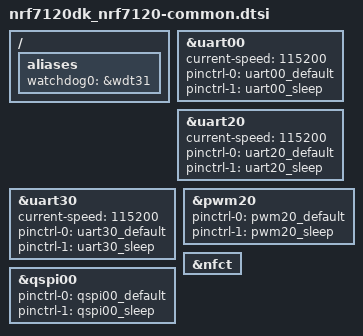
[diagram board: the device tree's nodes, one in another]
/*
 * Copyright (c) 2025 Nordic Semiconductor ASA
 *
 * SPDX-License-Identifier: LicenseRef-Nordic-5-Clause
 */

#include "nrf7120dk_nrf7120-pinctrl.dtsi"

/ {
	aliases {
		watchdog0 = &wdt31;
	};
};

&uart00 {
	current-speed = <115200>;
	pinctrl-0 = <&uart00_default>;
	pinctrl-1 = <&uart00_sleep>;
	pinctrl-names = "default", "sleep";
};

&uart20 {
	current-speed = <115200>;
	pinctrl-0 = <&uart20_default>;
	pinctrl-1 = <&uart20_sleep>;
	pinctrl-names = "default", "sleep";
};

&uart30 {
	current-speed = <115200>;
	pinctrl-0 = <&uart30_default>;
	pinctrl-1 = <&uart30_sleep>;
	pinctrl-names = "default", "sleep";
};

&pwm20 {
	status = "okay";
	pinctrl-0 = <&pwm20_default>;
	pinctrl-1 = <&pwm20_sleep>;
	pinctrl-names = "default", "sleep";
};

&nfct {
	status = "okay";
};

&qspi00 {
	pinctrl-0 = <&qspi00_default>;
	pinctrl-1 = <&qspi00_sleep>;
	pinctrl-names = "default", "sleep";
};
